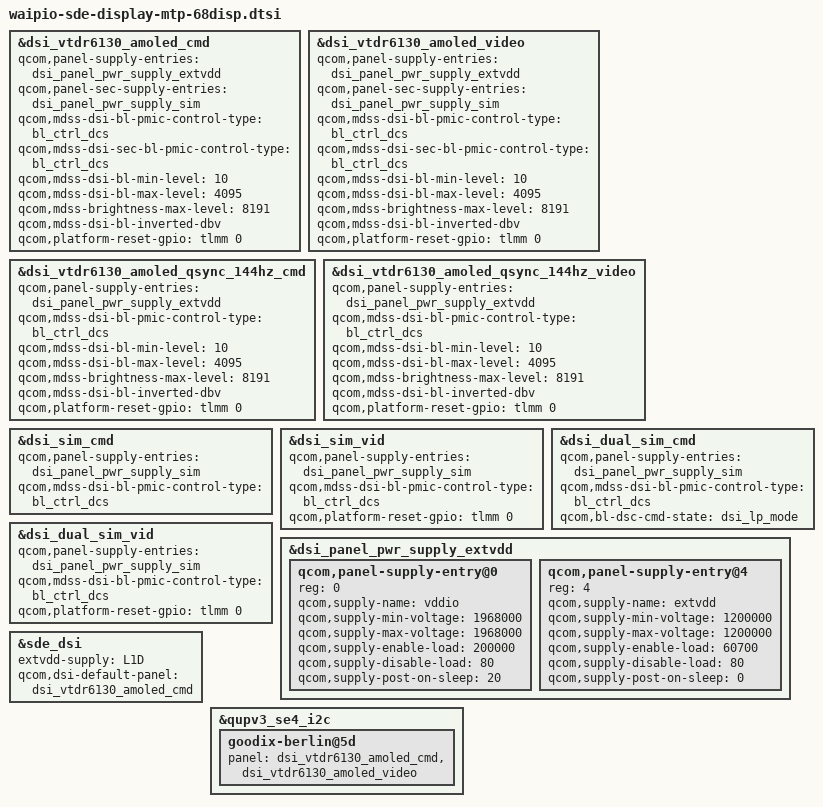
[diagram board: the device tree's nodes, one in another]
#include "waipio-sde-display.dtsi"

&dsi_vtdr6130_amoled_cmd {
	qcom,panel-supply-entries = <&dsi_panel_pwr_supply_extvdd>;
	qcom,panel-sec-supply-entries = <&dsi_panel_pwr_supply_sim>;
	qcom,mdss-dsi-bl-pmic-control-type = "bl_ctrl_dcs";
	qcom,mdss-dsi-sec-bl-pmic-control-type = "bl_ctrl_dcs";
	qcom,mdss-dsi-bl-min-level = <10>;
	qcom,mdss-dsi-bl-max-level = <4095>;
	qcom,mdss-brightness-max-level = <8191>;
	qcom,mdss-dsi-bl-inverted-dbv;
	qcom,platform-reset-gpio = <&tlmm 0 0>;
};

&dsi_vtdr6130_amoled_video {
	qcom,panel-supply-entries = <&dsi_panel_pwr_supply_extvdd>;
	qcom,panel-sec-supply-entries = <&dsi_panel_pwr_supply_sim>;
	qcom,mdss-dsi-bl-pmic-control-type = "bl_ctrl_dcs";
	qcom,mdss-dsi-sec-bl-pmic-control-type = "bl_ctrl_dcs";
	qcom,mdss-dsi-bl-min-level = <10>;
	qcom,mdss-dsi-bl-max-level = <4095>;
	qcom,mdss-brightness-max-level = <8191>;
	qcom,mdss-dsi-bl-inverted-dbv;
	qcom,platform-reset-gpio = <&tlmm 0 0>;
};

&dsi_vtdr6130_amoled_qsync_144hz_cmd {
	qcom,panel-supply-entries = <&dsi_panel_pwr_supply_extvdd>;
	qcom,mdss-dsi-bl-pmic-control-type = "bl_ctrl_dcs";
	qcom,mdss-dsi-bl-min-level = <10>;
	qcom,mdss-dsi-bl-max-level = <4095>;
	qcom,mdss-brightness-max-level = <8191>;
	qcom,mdss-dsi-bl-inverted-dbv;
	qcom,platform-reset-gpio = <&tlmm 0 0>;
};

&dsi_vtdr6130_amoled_qsync_144hz_video {
	qcom,panel-supply-entries = <&dsi_panel_pwr_supply_extvdd>;
	qcom,mdss-dsi-bl-pmic-control-type = "bl_ctrl_dcs";
	qcom,mdss-dsi-bl-min-level = <10>;
	qcom,mdss-dsi-bl-max-level = <4095>;
	qcom,mdss-brightness-max-level = <8191>;
	qcom,mdss-dsi-bl-inverted-dbv;
	qcom,platform-reset-gpio = <&tlmm 0 0>;
};

&dsi_sim_cmd {
	qcom,panel-supply-entries = <&dsi_panel_pwr_supply_sim>;
	qcom,mdss-dsi-bl-pmic-control-type = "bl_ctrl_dcs";
};

&dsi_sim_vid {
	qcom,panel-supply-entries = <&dsi_panel_pwr_supply_sim>;
	qcom,mdss-dsi-bl-pmic-control-type = "bl_ctrl_dcs";
	qcom,platform-reset-gpio = <&tlmm 0 0>;
};

&dsi_dual_sim_cmd {
	qcom,panel-supply-entries = <&dsi_panel_pwr_supply_sim>;
	qcom,mdss-dsi-bl-pmic-control-type = "bl_ctrl_dcs";
	qcom,bl-dsc-cmd-state = "dsi_lp_mode";
};

&dsi_dual_sim_vid {
	qcom,panel-supply-entries = <&dsi_panel_pwr_supply_sim>;
	qcom,mdss-dsi-bl-pmic-control-type = "bl_ctrl_dcs";
	qcom,platform-reset-gpio = <&tlmm 0 0>;
};

&dsi_panel_pwr_supply_extvdd {
	qcom,panel-supply-entry@0 {
		reg = <0>;
		qcom,supply-name = "vddio";
		qcom,supply-min-voltage = <1968000>;
		qcom,supply-max-voltage = <1968000>;
		qcom,supply-enable-load = <200000>;
		qcom,supply-disable-load = <80>;
		qcom,supply-post-on-sleep = <20>;
	};

	qcom,panel-supply-entry@4 {
		reg = <4>;
		qcom,supply-name = "extvdd";
		qcom,supply-min-voltage = <1200000>;
		qcom,supply-max-voltage = <1200000>;
		qcom,supply-enable-load = <60700>;
		qcom,supply-disable-load = <80>;
		qcom,supply-post-on-sleep = <0>;
	};
};

&sde_dsi {
	extvdd-supply = <&L1D>;
	qcom,dsi-default-panel = <&dsi_vtdr6130_amoled_cmd>;
};

&qupv3_se4_i2c {
	goodix-berlin@5d{
		panel = <&dsi_vtdr6130_amoled_cmd
		&dsi_vtdr6130_amoled_video>;
	};
};
